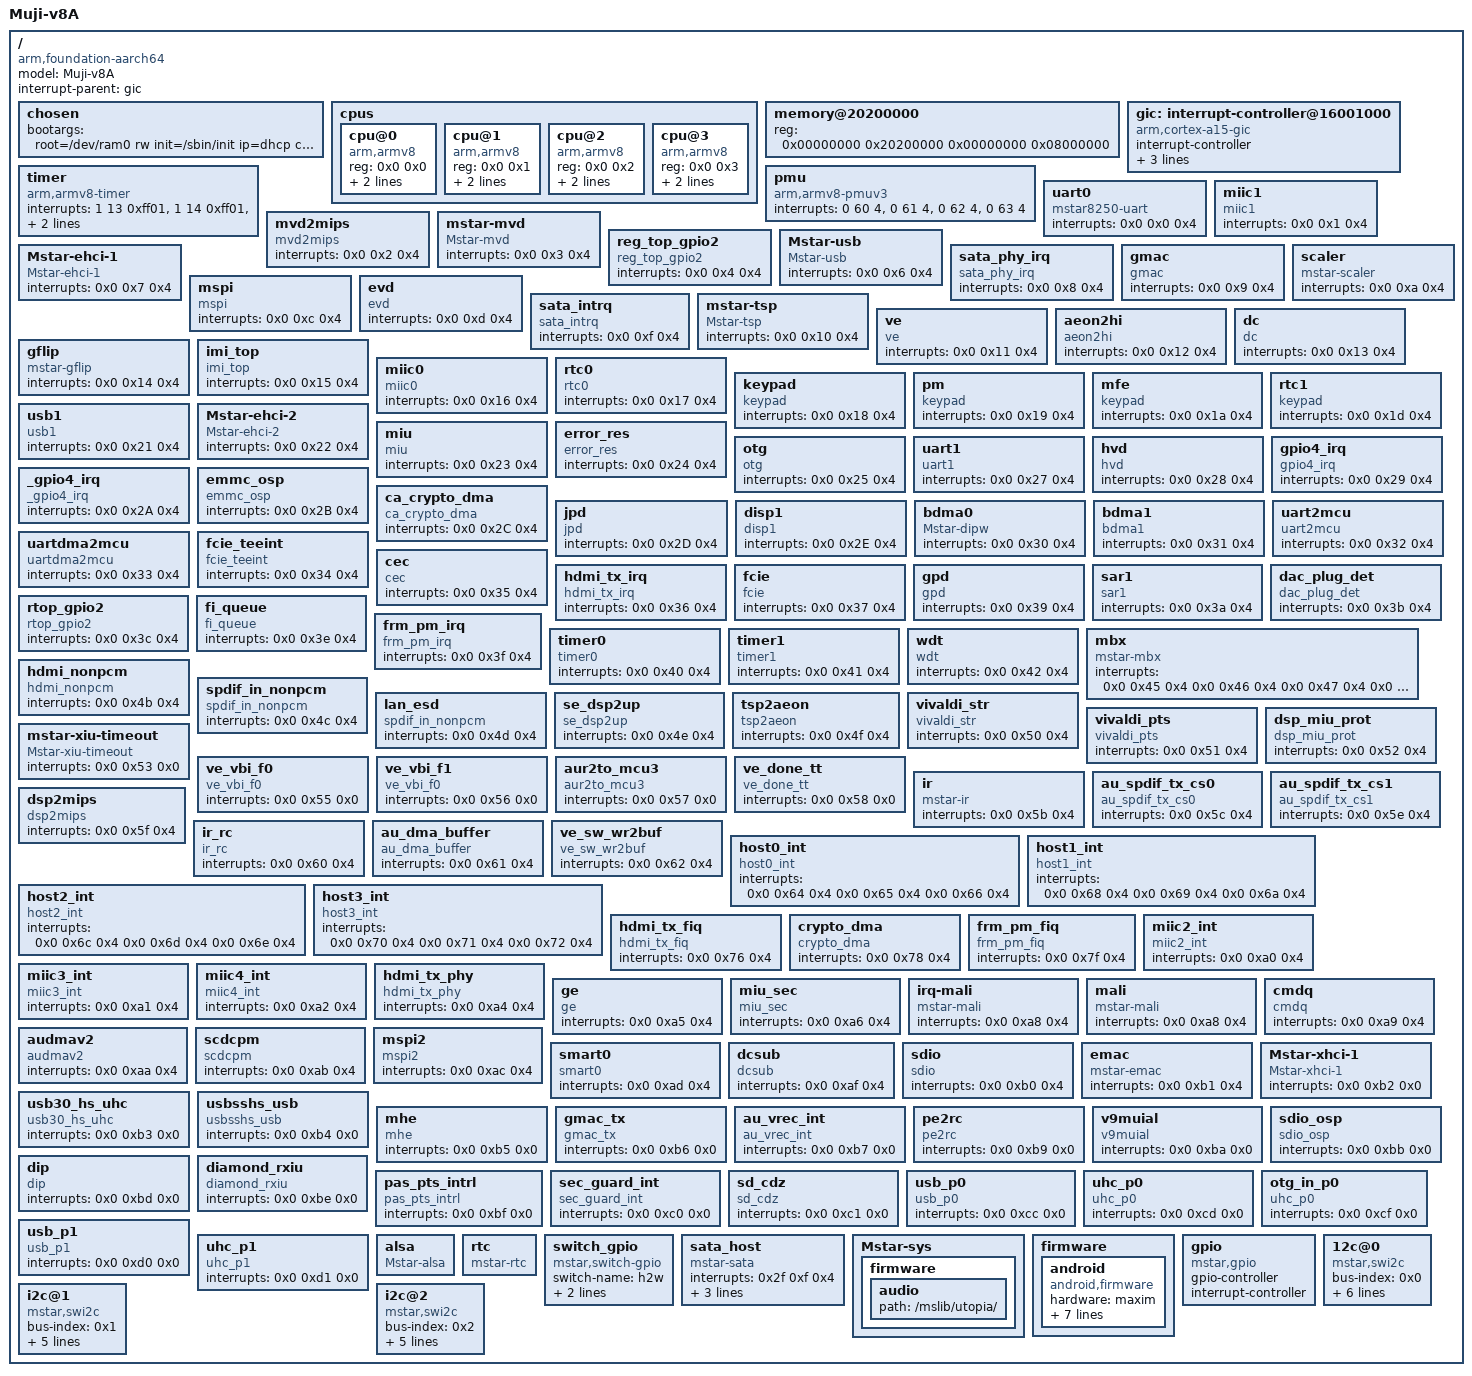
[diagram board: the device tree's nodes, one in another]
/*
 * ARM Ltd.
 *
 * ARMv8 Foundation model DTS
 */

/dts-v1/;
/ {
	model = "Muji-v8A";
	compatible = "arm,foundation-aarch64", "arm,muji";
	interrupt-parent = <&gic>;
	#address-cells = <2>;
	#size-cells = <2>;

    /* rdinit=/sbin/init */
	chosen {
         bootargs = "root=/dev/ram0 rw init=/sbin/init ip=dhcp console=ttyS0,115200,LX_MEM=0x02000000";
        };

	cpus {
		#address-cells = <2>;
		#size-cells = <0>;

		cpu@0 {
			device_type = "cpu";
			compatible = "arm,armv8";
			reg = <0x0 0x0>;
			enable-method = "mstar-spin-table";
			cpu-release-addr = <0x0 0x00100510>;
		};

                cpu@1 {
                        device_type = "cpu";
                        compatible = "arm,armv8";
                        reg = <0x0 0x1>;
                        enable-method = "mstar-spin-table";
                        cpu-release-addr = <0x0 0x00100510>;
                };

                 cpu@2 {
                        device_type = "cpu";
                        compatible = "arm,armv8";
                        reg = <0x0 0x2>;
                        enable-method = "mstar-spin-table";
                        cpu-release-addr = <0x0 0x00100510>;
                };


                 cpu@3{
                        device_type = "cpu";
                        compatible = "arm,armv8";
                        reg = <0x0 0x3>;
                        enable-method = "mstar-spin-table";
                        cpu-release-addr = <0x0 0x00100510>;
                };




	};

	memory@20200000 {
		device_type = "memory";
		reg = <0x00000000 0x20200000 0x00000000 0x08000000>;
	};

	gic: interrupt-controller@16001000 {
		compatible = "arm,cortex-a15-gic", "arm,cortex-a9-gic";
		#interrupt-cells = <3>;
		#address-cells = <0>;
		interrupt-controller;
		reg = <0x0 0x16001000 0 0x1000>,
		      <0x0 0x16002000 0 0x4000>;
		interrupts = <1 9 0xf04>;
	};

	timer {
		compatible = "arm,armv8-timer";
		interrupts = <1 13 0xff01>,
			     <1 14 0xff01>,
			     <1 11 0xff01>,
			     <1 10 0xff01>;
		clock-frequency = <12000000>;
	};

	pmu {
		compatible = "arm,armv8-pmuv3";
		interrupts = <0 60 4>,
			     <0 61 4>,
			     <0 62 4>,
			     <0 63 4>;
	};

	uart0 {
		compatible = "mstar8250-uart";
		interrupts = <0x0 0x0 0x4>;
	};

	miic1 {
		compatible = "miic1";
		interrupts = <0x0 0x1 0x4>;
	};

	mvd2mips {
		compatible = "mvd2mips";
		interrupts = <0x0 0x2 0x4>;
	};


	mstar-mvd {
		compatible = "Mstar-mvd";
		interrupts = <0x0 0x3 0x4>;
	};

	reg_top_gpio2 {
		compatible = "reg_top_gpio2";
		interrupts = <0x0 0x4 0x4>;
	};


	Mstar-usb {
		compatible = "Mstar-usb";
		interrupts = <0x0 0x6 0x4>;
	};


	Mstar-ehci-1 {
		compatible = "Mstar-ehci-1";
		interrupts = <0x0 0x7 0x4>;
	};

	sata_phy_irq {
		compatible = "sata_phy_irq";
		interrupts = <0x0 0x8 0x4>;
	};

	gmac{
		compatible = "gmac";
		interrupts = <0x0 0x9 0x4>;
	};

	scaler {
		compatible = "mstar-scaler";
		interrupts = <0x0 0xa 0x4>;
	};

	mspi   {
		compatible = "mspi";
		interrupts = <0x0 0xc 0x4>;
	};


	evd   {
		compatible = "evd";
		interrupts = <0x0 0xd 0x4>;
	};


	sata_intrq {
		compatible = "sata_intrq";
		interrupts = <0x0 0xf 0x4>;
	};


	mstar-tsp {
		compatible = "Mstar-tsp";
		interrupts = <0x0 0x10 0x4>;
	};

	ve {
		compatible = "ve";
		interrupts = <0x0 0x11 0x4>;
	};

	aeon2hi {
		compatible = "aeon2hi";
		interrupts = <0x0 0x12 0x4>;
	};

	dc {
		compatible = "dc";
		interrupts = <0x0 0x13 0x4>;
	};


	gflip {
		compatible = "mstar-gflip";
		interrupts = <0x0 0x14 0x4>;
	};

	imi_top {
		compatible = "imi_top";
		interrupts = <0x0 0x15 0x4>;
	};

	miic0 {
		compatible = "miic0";
		interrupts = <0x0 0x16 0x4>;
	};

	rtc0 {
		compatible = "rtc0";
		interrupts = <0x0 0x17 0x4>;
	};

	keypad{
		compatible = "keypad";
		interrupts = <0x0 0x18 0x4>;
	};

	pm {
		compatible = "keypad";
		interrupts = <0x0 0x19 0x4>;
	};

	mfe {
		compatible = "keypad";
		interrupts = <0x0 0x1a 0x4>;
	};

	rtc1 {
		compatible = "keypad";
		interrupts = <0x0 0x1d 0x4>;
	};

	usb1 {
		compatible = "usb1";
		interrupts = <0x0 0x21 0x4>;
	};

	Mstar-ehci-2 {
		compatible = "Mstar-ehci-2";
		interrupts = <0x0 0x22 0x4>;
	};

	miu {
		compatible = "miu";
		interrupts = <0x0 0x23 0x4>;
	};

	error_res {
		compatible = "error_res";
		interrupts = <0x0 0x24 0x4>;
	};

	otg {
		compatible = "otg";
		interrupts = <0x0 0x25 0x4>;
	};

	uart1 {
		compatible = "uart1";
		interrupts = <0x0 0x27 0x4>;
	};

	hvd {
		compatible = "hvd";
		interrupts = <0x0 0x28 0x4>;
	};

	gpio4_irq {
		compatible = "gpio4_irq";
		interrupts = <0x0 0x29 0x4>;
	};

	_gpio4_irq {
		compatible = "_gpio4_irq";
		interrupts = <0x0 0x2A 0x4>;
	};

	emmc_osp {
		compatible = "emmc_osp";
		interrupts = <0x0 0x2B 0x4>;
	};

	ca_crypto_dma {
		compatible = "ca_crypto_dma";
		interrupts = <0x0 0x2C 0x4>;
	};

	jpd {
		compatible = "jpd";
		interrupts = <0x0 0x2D 0x4>;
	};

	disp1 {
		compatible = "disp1";
		interrupts = <0x0 0x2E 0x4>;
	};

	bdma0 {
		compatible = "Mstar-dipw";
		interrupts = <0x0 0x30 0x4>;
	};

	bdma1 {
		compatible = "bdma1";
		interrupts = <0x0 0x31 0x4>;
	};

	uart2mcu {
		compatible = "uart2mcu";
		interrupts = <0x0 0x32 0x4>;
	};

	uartdma2mcu {
		compatible = "uartdma2mcu";
		interrupts = <0x0 0x33 0x4>;
	};

	fcie_teeint {
		compatible = "fcie_teeint";
		interrupts = <0x0 0x34 0x4>;
	};


	cec{
		compatible = "cec";
		interrupts = <0x0 0x35 0x4>;
	};

	hdmi_tx_irq{
		compatible = "hdmi_tx_irq";
		interrupts = <0x0 0x36 0x4>;
	};


	fcie {
		compatible = "fcie";
		interrupts = <0x0 0x37 0x4>;
	};

	gpd {
		compatible = "gpd ";
		interrupts = <0x0 0x39 0x4>;
	};

	sar1 {
		compatible = "sar1";
		interrupts = <0x0 0x3a 0x4>;
	};

	dac_plug_det{
		compatible = "dac_plug_det";
		interrupts = <0x0 0x3b 0x4>;
	};

	rtop_gpio2 {
		compatible = "rtop_gpio2 ";
		interrupts = <0x0 0x3c 0x4>;
	};

	fi_queue {
		compatible = "fi_queue";
		interrupts = <0x0 0x3e 0x4>;
	};

	frm_pm_irq {
		compatible = "frm_pm_irq";
		interrupts = <0x0 0x3f 0x4>;
	};

	timer0{
		compatible = "timer0";
		interrupts = <0x0 0x40 0x4>;
	};

	timer1{
		compatible = "timer1";
		interrupts = <0x0 0x41 0x4>;
	};

	wdt {
		compatible = "wdt";
		interrupts = <0x0 0x42 0x4>;
	};

	mbx {
		compatible = "mstar-mbx";
		interrupts = <0x0 0x45 0x4 0x0 0x46 0x4  0x0 0x47 0x4  0x0 0x48 0x4 0x0 0x4a 0x4>;
	};


	hdmi_nonpcm {
		compatible = "hdmi_nonpcm";
		interrupts = <0x0 0x4b 0x4>;
	};

	spdif_in_nonpcm {
		compatible = "spdif_in_nonpcm";
		interrupts = <0x0 0x4c 0x4>;
	};

	lan_esd {
		compatible = "spdif_in_nonpcm";
		interrupts = <0x0 0x4d 0x4>;
	};

	se_dsp2up {
		compatible = "se_dsp2up";
		interrupts = <0x0 0x4e 0x4>;
	};

	tsp2aeon {
		compatible = "tsp2aeon";
		interrupts = <0x0 0x4f 0x4>;
	};

	vivaldi_str {
		compatible = "vivaldi_str";
		interrupts = <0x0 0x50 0x4>;
	};

	vivaldi_pts {
		compatible = "vivaldi_pts";
		interrupts = <0x0 0x51 0x4>;
	};

	dsp_miu_prot {
		compatible = "dsp_miu_prot";
		interrupts = <0x0 0x52 0x4>;
	};

	mstar-xiu-timeout {
		compatible = "Mstar-xiu-timeout";
		interrupts = <0x0 0x53 0x0>;
	};

        ve_vbi_f0 {
		compatible = "ve_vbi_f0";
		interrupts = <0x0 0x55 0x0>;

        };

        ve_vbi_f1 {
		compatible = "ve_vbi_f0";
		interrupts = <0x0 0x56 0x0>;

        };

        aur2to_mcu3 {
		compatible = "aur2to_mcu3";
		interrupts = <0x0 0x57 0x0>;

        };

        ve_done_tt {
		compatible = "ve_done_tt";
		interrupts = <0x0 0x58 0x0>;

        };


	ir {
		compatible = "mstar-ir";
		interrupts = <0x0 0x5b 0x4>;
	};


	au_spdif_tx_cs0 {
		compatible = "au_spdif_tx_cs0";
		interrupts = <0x0 0x5c 0x4>;
	};

	au_spdif_tx_cs1 {
		compatible = "au_spdif_tx_cs1";
		interrupts = <0x0 0x5e 0x4>;
	};

	dsp2mips {
		compatible = "dsp2mips";
		interrupts = <0x0 0x5f 0x4>;
	};

	ir_rc {
		compatible = "ir_rc";
		interrupts = <0x0 0x60 0x4>;
	};

	au_dma_buffer {
		compatible = "au_dma_buffer";
		interrupts = <0x0 0x61 0x4>;
	};

	ve_sw_wr2buf {
		compatible = "ve_sw_wr2buf";
		interrupts = <0x0 0x62 0x4>;
	};

	host0_int {
		compatible = "host0_int";
		interrupts = <0x0 0x64 0x4  0x0 0x65 0x4  0x0 0x66 0x4>;
	};

	host1_int {
		compatible = "host1_int";
		interrupts = <0x0 0x68 0x4  0x0 0x69 0x4  0x0 0x6a 0x4>;
	};

	host2_int {
		compatible = "host2_int";
		interrupts = <0x0 0x6c 0x4  0x0 0x6d 0x4  0x0 0x6e 0x4>;
	};

	host3_int {
		compatible = "host3_int";
		interrupts = <0x0 0x70 0x4  0x0 0x71 0x4  0x0 0x72 0x4>;
	};

	hdmi_tx_fiq {
		compatible = "hdmi_tx_fiq";
		interrupts = <0x0 0x76 0x4>;
	};

	crypto_dma {
		compatible = "crypto_dma";
		interrupts = <0x0 0x78 0x4>;
	};

	frm_pm_fiq {
		compatible = "frm_pm_fiq";
		interrupts = <0x0 0x7f 0x4>;
	};


	miic2_int {
		compatible = "miic2_int";
		interrupts = <0x0 0xa0 0x4>;
	};

	miic3_int {
		compatible = "miic3_int";
		interrupts = <0x0 0xa1 0x4>;
	};

	miic4_int {
		compatible = "miic4_int";
		interrupts = <0x0 0xa2 0x4>;
	};


	hdmi_tx_phy {
		compatible = "hdmi_tx_phy";
		interrupts = <0x0 0xa4 0x4>;
	};


	ge {
		compatible = "ge";
		interrupts = <0x0 0xa5 0x4>;
	};

	miu_sec {
		compatible = "miu_sec";
		interrupts = <0x0 0xa6 0x4>;
	};

	irq-mali {
		compatible = "mstar-mali";
		interrupts = <0x0 0xa8 0x4>;
	};

        mali {
		compatible = "mstar-mali";
		interrupts = <0x0 0xa8 0x4>;
	};

        cmdq {
		compatible = "cmdq";
		interrupts = <0x0 0xa9 0x4>;
	};

        audmav2 {
		compatible = "audmav2";
		interrupts = <0x0 0xaa 0x4>;
	};

        scdcpm {
		compatible = "scdcpm";
		interrupts = <0x0 0xab 0x4>;
	};

        mspi2 {
		compatible = "mspi2";
		interrupts = <0x0 0xac 0x4>;
	};

        smart0 {
		compatible = "smart0";
		interrupts = <0x0 0xad 0x4>;
	};

        dcsub {
		compatible = "dcsub";
		interrupts = <0x0 0xaf 0x4>;
	};

	sdio {
		compatible = "sdio";
		interrupts = <0x0 0xb0 0x4>;
	};

        emac {
		compatible = "mstar-emac";
		interrupts = <0x0 0xb1 0x4>;
	};

	Mstar-xhci-1 {
		compatible = "Mstar-xhci-1";
		interrupts = <0x0 0xb2 0x0>;
	};

	usb30_hs_uhc {
		compatible = "usb30_hs_uhc";
		interrupts = <0x0 0xb3 0x0>;
	};

	usbsshs_usb {
		compatible = "usbsshs_usb";
		interrupts = <0x0 0xb4 0x0>;
	};


	mhe {
		compatible = "mhe";
		interrupts = <0x0 0xb5 0x0>;
	};

	gmac_tx {
		compatible = "gmac_tx";
		interrupts = <0x0 0xb6 0x0>;
	};

	au_vrec_int {
		compatible = "au_vrec_int";
		interrupts = <0x0 0xb7 0x0>;
	};

	pe2rc {
		compatible = "pe2rc";
		interrupts = <0x0 0xb9 0x0>;
	};

	v9muial {
		compatible = "v9muial";
		interrupts = <0x0 0xba 0x0>;
	};

	sdio_osp {
		compatible = "sdio_osp";
		interrupts = <0x0 0xbb 0x0>;
	};

	dip {
		compatible = "dip";
		interrupts = <0x0 0xbd 0x0>;
	};

	diamond_rxiu {
		compatible = "diamond_rxiu";
		interrupts = <0x0 0xbe 0x0>;
	};

        pas_pts_intrl {
		compatible = "pas_pts_intrl";
		interrupts = <0x0 0xbf 0x0>;
	};


	sec_guard_int {
		compatible = "sec_guard_int";
		interrupts = <0x0 0xc0 0x0>;
	};

	sd_cdz {
		compatible = "sd_cdz";
		interrupts = <0x0 0xc1 0x0>;
	};

	usb_p0 {
		compatible = "usb_p0";
		interrupts = <0x0 0xcc 0x0>;
	};

	uhc_p0 {
		compatible = "uhc_p0";
		interrupts = <0x0 0xcd 0x0>;
	};

	otg_in_p0 {
		compatible = "uhc_p0";
		interrupts = <0x0 0xcf 0x0>;
	};

	usb_p1 {
		compatible = "usb_p1";
		interrupts = <0x0 0xd0 0x0>;
	};

	uhc_p1 {
		compatible = "uhc_p1";
		interrupts = <0x0 0xd1 0x0>;
	};


	alsa {
		compatible = "Mstar-alsa";
	};

	rtc {
		compatible = "mstar-rtc";
	};

	switch_gpio {
		compatible = "mstar,switch-gpio";
		switch-name = "h2w";
		switch-gpio = <999>;
		switch-inverse = <0>;
	};

	sata_host {
		compatible = "mstar-sata";
		interrupts = <0x2f 0xf 0x4>;
		mstar,hba-base =  <0x102B00>;
		mstar,port-base = <0x102C00>;
		mstar,misc-base = <0x102D00>;
	};

	Mstar-sys {
		firmware {
			audio {
				path = "/mslib/utopia/";
			};
		};
	};

	firmware {

		android {
			compatible = "android,firmware";
			hardware = "maxim";
			revision = "1234";
			Serial = "0000000000000000";
			Processor = "AArch64 Processor rev 3 (aarch64)";
			serialno = "123456789";
			mode = "123456789";
			baseband = "123456789";
			bootloader = "123456789";
		};
	};

	gpio {
		compatible = "mstar,gpio";
		gpio-controller;
		#gpio-cells = <0x1>;
		interrupt-controller;
		#interrupt-cells = <0x2>;
	};

	12c@0 {
		compatible = "mstar,swi2c";
		bus-index = <0x0>;
		sda-gpio = <0x39>;
		scl-gpio = <0x38>;
		speed-khz = <0x64>;
		def-delay = <0x64>;
		retries = <0x5>;
		staus = "okay";
		#address-cells = <0x1>;
		#size-cells = <0x0>;
	};

	i2c@1 {
		compatible = "mstar,swi2c";
		bus-index = <0x1>;
		sda-gpio = <0x9a>;
		scl-gpio = <0x99>;
		speed-khz = <0x64>;
		def-delay = <0x64>;
		retries = <0x5>;
		status = "okay";
	};

	i2c@2 {
		compatible = "mstar,swi2c";
		bus-index = <0x2>;
		sda-gpio = <0x4e>;
		scl-gpio = <0x4d>;
		speed-khz = <0x64>;
		def-delay = <0x64>;
		retries = <0x5>;
		status = "okay";
	};




};
